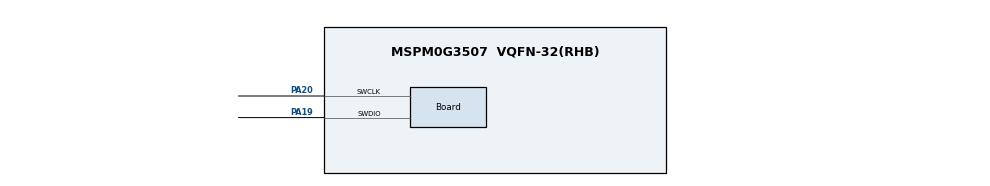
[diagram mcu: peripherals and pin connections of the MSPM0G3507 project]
/**
 * These arguments were used when this file was generated. They will be automatically applied on subsequent loads
 * via the GUI or CLI. Run CLI with '--help' for additional information on how to override these arguments.
 * @cliArgs --device "MSPM0G350X" --part "Default" --package "VQFN-32(RHB)" --product "mspm0_sdk@2.04.00.06"
 * @v2CliArgs --device "MSPM0G3507" --package "VQFN-32(RHB)" --product "mspm0_sdk@2.04.00.06"
 * @versions {"tool":"1.23.0+4000"}
 */

/**
 * Import the modules used in this configuration.
 */
const CRC    = scripting.addModule("/ti/driverlib/CRC");
const I2C    = scripting.addModule("/ti/driverlib/I2C", {}, false);
const I2C1   = I2C.addInstance();
const SYSCTL = scripting.addModule("/ti/driverlib/SYSCTL");

/**
 * Write custom configuration values to the imported modules.
 */
CRC.polynomial = "16_POLYNOMIAL";
CRC.seed       = 0xFFFF;

const Board                       = scripting.addModule("/ti/driverlib/Board", {}, false);
Board.peripheral.$assign          = "DEBUGSS";
Board.peripheral.swclkPin.$assign = "PA20";
Board.peripheral.swdioPin.$assign = "PA19";

I2C1.$name                     = "I2C_0";
I2C1.basicEnableController     = true;
I2C1.intController             = ["NACK","RXFIFO_TRIGGER","RX_DONE","TX_DONE"];
I2C1.sdaPinConfig.$name        = "ti_driverlib_gpio_GPIOPinGeneric0";
I2C1.sclPinConfig.$name        = "ti_driverlib_gpio_GPIOPinGeneric1";
I2C1.sclPinConfig.enableConfig = true;

SYSCTL.forceDefaultClkConfig = true;
SYSCTL.clockTreeEn           = true;

const ProjectConfig              = scripting.addModule("/ti/project_config/ProjectConfig", {}, false);
ProjectConfig.migrationCondition = true;

/**
 * Pinmux solution for unlocked pins/peripherals. This ensures that minor changes to the automatic solver in a future
 * version of the tool will not impact the pinmux you originally saw.  These lines can be completely deleted in order to
 * re-solve from scratch.
 */
I2C1.peripheral.$suggestSolution        = "I2C1";
I2C1.peripheral.sdaPin.$suggestSolution = "PA10";
I2C1.peripheral.sclPin.$suggestSolution = "PA11";
